# DA14586 register map
Vendor: Dialog; Series: DA1458x; File version: 1.2
CPU: CM0 r1p0, little endian, MPU, FPU, 3 interrupt priority bits
Registers are 16-bit, read-write, reset 0x0 unless marked. A register's access mark holds for its fields unless they carry their own. Offsets are from the block's base; [hi:lo] are bit positions.

## rfpt580_gr01 — rfpt580_gr01 registers
Base 0x50003500
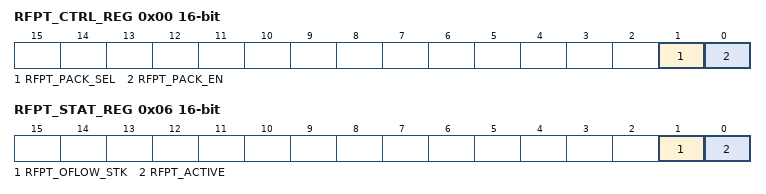
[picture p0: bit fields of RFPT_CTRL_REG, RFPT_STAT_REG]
0x00 RFPT_CTRL_REG — Control register
  [1] RFPT_PACK_SEL — Selects the source of data that will be captured. 0 - Will capture the output of the two ADC. 1 - Will capture the output of the Phase Detector.
  [0] RFPT_PACK_EN — Starts the capturing of the data from the selected source ( RFPT_PACK_SEL ). 0 - There is no capturing of data. The packer of data is idle. 1 - The controller captures data. The packing of the data in words, is in progress. Should be written with 1 in order to start the acquisition of data. After the acquisition of a predefined number of words ( RFPT_LEN ), this bit will be auto cleared.
0x02 RFPT_ADDR_REG — AHB master start address
  [15:2] RFPT_ADDR — It is the AHB address used by the AHB-Lite master interface of the controller (the bits [15:2]).
0x04 RFPT_LEN_REG — Data length register
  [13:0] RFPT_LEN — The number of words (minus one) that should be transfered. When the selected source of data is the two ADC ( RFPT_PACK_SEL ==0), will capture 2*( RFPT_LEN + 1) samples from each ADC. Otherwise ( RFPT_PACK_SEL ==1), will capture 4*( RFPT_LEN + 1) samples from the Phase Detector.
0x06 RFPT_STAT_REG — Status register
  [1] RFPT_OFLOW_STK — Indicates that during the transfer of the data, at least one overflow has detected to the fifo. 0 - The transfer completed without overflows. 1 - At least one overflow occured in the fifo. Write 1 to clear this bit.
  [0] RFPT_ACTIVE ro — Indicates the state of the controller. 0 - The controller is idle. 1 - The controller is active. The capturing process and/or the dma activity is in progress. The controller will activated (RFPT_ACTIVE == 1), when RFPT_PACK_EN will be written with 1. Will return to inactive state, after the end of the capturing process (RFPT_PACK_EN==0) and the transfer of all of the data to the memory.

## riscutil580_gpreg_nl01 — riscutil580_gpreg_nl01 registers
Base 0x50003300
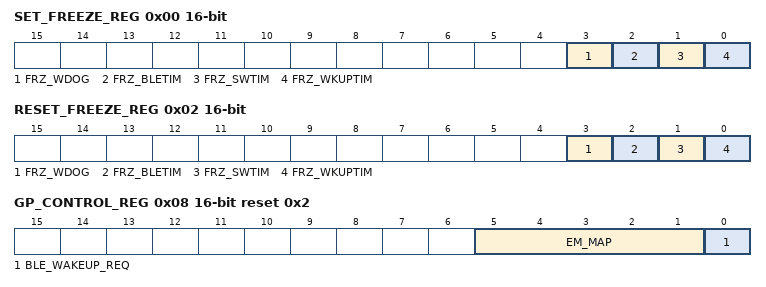
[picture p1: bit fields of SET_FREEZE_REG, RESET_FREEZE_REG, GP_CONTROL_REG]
0x00 SET_FREEZE_REG — Controls freezing of various timers/counters.
  [3] FRZ_WDOG — If '1', the watchdog timer is frozen, '0' is discarded. WATCHDOG_CTRL_REG[NMI_RST] must be '0' to allow the freeze function.
  [2] FRZ_BLETIM — If '1', the BLE master clock is frozen, '0' is discarded.
  [1] FRZ_SWTIM — If '1', the SW Timer (TIMER0) is frozen, '0' is discarded.
  [0] FRZ_WKUPTIM — If '1', the Wake Up Timer is frozen, '0' is discarded.
0x02 RESET_FREEZE_REG — Controls unfreezing of various timers/counters.
  [3] FRZ_WDOG — If '1', the watchdog timer continues, '0' is discarded.
  [2] FRZ_BLETIM — If '1', the the BLE master clock continues, '0' is discarded.
  [1] FRZ_SWTIM — If '1', the SW Timer (TIMER0) continues, '0' is discarded.
  [0] FRZ_WKUPTIM — If '1', the Wake Up Timer continues, '0' is discarded.
0x04 DEBUG_REG reset 0x1 — Various debug information register.
  [0] DEBUGS_FREEZE_EN — Default '1', freezing of the on-chip timers is enabled when the Cortex-M0 is halted in DEBUG State. If '0', freezing of the on-chip timers is depending on FREEZE_REG when the Cortex-M0 is halted in DEBUG State except the watchdog timer. The watchdog timer is always frozen when the Cortex-M0 is halted in DEBUG State.
0x06 GP_STATUS_REG — General purpose system status register.
  [0] CAL_PHASE — If '1', it designates that the chip is in Calibration Phase i.e. the OTP has been initially programmed but no Calibration has occured.
0x08 GP_CONTROL_REG reset 0x2 — General purpose system control register.
  [5:1] EM_MAP — Select the mapping of the Exchange memory pages. 0: EM size 0 kB, SysRAM size 42 kB 1: EM size 2 kB, SysRAM size 48 kB 2: EM size 3 kB, SysRAM size 47 kB 3: EM size 4 kB, SysRAM size 46 kB 4: EM size 5 kB, SysRAM size 45 kB 5: EM size 6 kB, SysRAM size 44 kB 6: EM size 7 kB, SysRAM size 43 kB 7: EM size 8 kB, SysRAM size 42 kB 8: Reserved 9: EM size 4 kB, SysRAM size 40 kB 10: EM size 5 kB, SysRAM size 40 kB 11: EM size 6 kB, SysRAM size 40 kB 12: EM size 7 kB, SysRAM size 40 kB 13: EM size 8 kB, SysRAM size 40 kB 14: EM size 9 kB, SysRAM size 40 kB 15: EM size 10 kB, SysRAM size 40 kB 16: Reserved 17: EM size 6 kB, SysRAM size 38 kB 18: EM size 7 kB, SysRAM size 38 kB 19: EM size 8 kB, SysRAM size 38 kB 20: EM size 9 kB, SysRAM size 38 kB 21: EM size 10 kB, SysRAM size 38 kB 22: EM size 11 kB, SysRAM size 38 kB 23: EM size 12 kB, SysRAM size 38 kB other: Reserved.
  [0] BLE_WAKEUP_REQ — If '1', the BLE wakes up. Must be kept high at least for 1 low power clock period. If the BLE is in deep sleep state, then by setting this bit it will cause the wakeup LP IRQ to be asserted with a delay of 3 to 4 low power cycles.
